AUTOSAR XML (schema 4.0)
standard types defined: float32, float64, sint16, sint32, sint8, uint16, uint32, uint8, void, boolean
package /ImplDataTypes
  4 x impl type, all with category=TYPE_REFERENCE, implementation-data-type=uint8, type-emitter=RTE:
    MultiStateBtnType
    SeatModeBtnType
    SensorPositiontype
    SensorWeightType
package /MappingSets
  data type mapping set MappingSet: mode-request-type-map{implementation-data-type=uint8, mode-group=SeatCtrlMode}
package /PortInterfaces/ClientServer
  10 x client server interface:
    CsIf_HeightMotor
      operation Opr_HeightMotorMove
        arg Arg_step: type=uint8, direction=IN
    CsIf_HeightSensor
      operation HeightSensor_GetPosition
        arg position: type=SensorPositiontype, direction=OUT
    CsIf_InclineMotor
      operation Opr_InclineMotorMove
        arg Arg_step: type=uint8, direction=IN
    CsIf_InclineSensor
      operation InclineSensor_GetPosition
        arg position: type=uint32, direction=OUT
    CsIf_IoGetSensorPosition
      operation IoGet
        arg position: type=SensorPositiontype, direction=OUT
    CsIf_IoGetSensorWeight
      operation IoGet
        arg weight: type=uint8, direction=OUT
    CsIf_IoSetMotor
      operation IoSetForward
      operation IoSetReverse
    CsIf_SlideMotor
      operation Opr_SlideMotorMove
        arg Arg_step: type=uint8, direction=IN
    CsIf_SlideSensor
      operation SlideSensor_GetPosition
        arg position: type=SensorPositiontype, direction=OUT
    CsIf_WeightSensor
      operation GetWeight
        arg weight: type=SensorWeightType, direction=OUT
package /PortInterfaces/ModeSwitch
  mode switch interface MsIf_SeatCtrlMode
    mode group SeatCtrlMode: type=SeatCtrlMode
  mode declaration group SeatCtrlMode: category=ALPHABETIC_ORDER, initial-mode=INIT, on-transition-value=255
    mode AUTO
    mode INIT
    mode MANUAL
package /PortInterfaces/SenderReceiver
  sender receiver interface SrIf_SeatCtrlBtns
    data HeightBtnState: type=MultiStateBtnType
    data InclineBtnState: type=MultiStateBtnType
    data SlideBtnState: type=MultiStateBtnType
  sender receiver interface SrIf_SeatCtrlData
    data DE_Height: type=uint8
    data DE_Incline: type=uint8
    data DE_Slide: type=uint8
  sender receiver interface SrIf_SeatModeBtn
    data DE_SeatModeBtn: type=SeatModeBtnType
package /SoftwareComponents
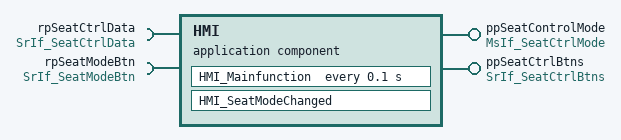
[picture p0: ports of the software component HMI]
  application sw component type HMI
    provide port ppSeatControlMode: provided-interface=MsIf_SeatCtrlMode
    provide port ppSeatCtrlBtns: provided-interface=SrIf_SeatCtrlBtns
    require port rpSeatCtrlData: required-interface=SrIf_SeatCtrlData
    require port rpSeatModeBtn: required-interface=SrIf_SeatModeBtn
    behavior Ibhv_HMI: data-type-mapping=MappingSet, handle-termination-and-restart=NO-SUPPORT
      data received event DRE_rpSeatModeBtn_DE_SeatModeBtn: start-on-event=HMI_SeatModeChanged, data=rpSeatModeBtn.DE_SeatModeBtn
      timing event TE_HMI_Mainfunction_100ms: start-on-event=HMI_Mainfunction, period=0.1
      runnable HMI_Mainfunction
        data-receive-point-by-arguments:
          access DRP_rpSeatCtrlData_DE_Height: accessed-variable=rpSeatCtrlData.DE_Height
          access DRP_rpSeatCtrlData_DE_Incline: accessed-variable=rpSeatCtrlData.DE_Incline
          access DRP_rpSeatCtrlData_DE_Slide: accessed-variable=rpSeatCtrlData.DE_Slide
        data-send-points:
          access DSP_ppSeatCtrlBtns_HeightBtnState: accessed-variable=ppSeatCtrlBtns.HeightBtnState
          access DSP_ppSeatCtrlBtns_InclineBtnState: accessed-variable=ppSeatCtrlBtns.InclineBtnState
          access DSP_ppSeatCtrlBtns_SlideBtnState: accessed-variable=ppSeatCtrlBtns.SlideBtnState
      runnable HMI_SeatModeChanged
        data-receive-point-by-arguments:
          access DRP_rpSeatModeBtn_DE_SeatModeBtn: accessed-variable=rpSeatModeBtn.DE_SeatModeBtn
        mode switch point MSP_ppSeatControlMode_ppSeatControlMode: mode-group=ppSeatControlMode.SeatCtrlMode
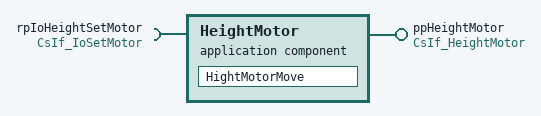
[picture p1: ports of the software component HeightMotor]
  application sw component type HeightMotor
    provide port ppHeightMotor: provided-interface=CsIf_HeightMotor
    require port rpIoHeightSetMotor: required-interface=CsIf_IoSetMotor
    behavior Ibhv_HeightMotor: data-type-mapping=MappingSet, handle-termination-and-restart=NO-SUPPORT
      operation invoked event OIE_ppHeightMotor_Opr_HeightMotorMove: start-on-event=HightMotorMove, operation=ppHeightMotor.Opr_HeightMotorMove
      runnable HightMotorMove
        sync call SCP_rpIoHeightSetMotor_IoSetForward: operation=rpIoHeightSetMotor.IoSetForward, timeout=0.0
        sync call SCP_rpIoHeightSetMotor_IoSetReverse: operation=rpIoHeightSetMotor.IoSetReverse, timeout=0.0
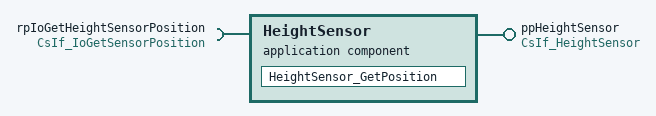
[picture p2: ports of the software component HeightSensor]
  application sw component type HeightSensor
    provide port ppHeightSensor: provided-interface=CsIf_HeightSensor
    require port rpIoGetHeightSensorPosition: required-interface=CsIf_IoGetSensorPosition
    behavior Ibhv_HeightSensor: data-type-mapping=MappingSet, handle-termination-and-restart=NO-SUPPORT
      operation invoked event OIE_ppHeightSensor_HeightSensor_GetPosition: start-on-event=HeightSensor_GetPosition, operation=ppHeightSensor.HeightSensor_GetPosition
      runnable HeightSensor_GetPosition
        sync call SCP_rpIoGetHeightSensorPosition_IoGet: operation=rpIoGetHeightSensorPosition.IoGet, timeout=0.0
  10 x swc implementation, all with programming-language=C, sw-version=1.0.0, vendor-id=255:
    Impl_HMI: behavior=Ibhv_HMI
      code-descriptors:
        code Code: artifact-descriptors=autosar-engineering-object={short-label=SWC.c, category=SWSRC}
      resource consumption ResourceConsumption
    Impl_HeightMotor: behavior=Ibhv_HeightMotor
      code-descriptors:
        code Code: artifact-descriptors=autosar-engineering-object={short-label=SWC.c, category=SWSRC}
      resource consumption ResourceConsumption
    Impl_HeightSensor: behavior=Ibhv_HeightSensor
      code-descriptors:
        code Code: artifact-descriptors=autosar-engineering-object={short-label=SWC.c, category=SWSRC}
      resource consumption ResourceConsumption
    Impl_InclineMotor: behavior=Ibhv_InclineMotor
      code-descriptors:
        code Code: artifact-descriptors=autosar-engineering-object={short-label=SWC.c, category=SWSRC}
      resource consumption ResourceConsumption
    Impl_InclineSensor: behavior=Ibhv_InclineSensor
      code-descriptors:
        code Code: artifact-descriptors=autosar-engineering-object={short-label=SWC.c, category=SWSRC}
      resource consumption ResourceConsumption
    Impl_IoHwAbs: behavior=Ibhv_IoHwAbs
      code-descriptors:
        code Code: artifact-descriptors=autosar-engineering-object={short-label=SWC.c, category=SWSRC}
      resource consumption ResourceConsumption
    Impl_Seat_Manager: behavior=Ibhv_Seat_Manager
      code-descriptors:
        code Code: artifact-descriptors=autosar-engineering-object={short-label=SWC.c, category=SWSRC}
      resource consumption ResourceConsumption
    Impl_SlideMotor: behavior=Ibhv_SlideMotor
      code-descriptors:
        code Code: artifact-descriptors=autosar-engineering-object={short-label=SWC.c, category=SWSRC}
      resource consumption ResourceConsumption
    Impl_SlideSensor: behavior=Ibhv_SlideSensor
      code-descriptors:
        code Code: artifact-descriptors=autosar-engineering-object={short-label=SWC.c, category=SWSRC}
      resource consumption ResourceConsumption
    Impl_WeightSensor: behavior=Ibhv_WeightSensor
      code-descriptors:
        code Code: artifact-descriptors=autosar-engineering-object={short-label=SWC.c, category=SWSRC}
      resource consumption ResourceConsumption
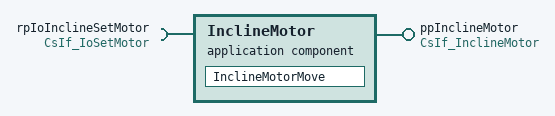
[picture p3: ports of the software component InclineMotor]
  application sw component type InclineMotor
    provide port ppInclineMotor: provided-interface=CsIf_InclineMotor
    require port rpIoInclineSetMotor: required-interface=CsIf_IoSetMotor
    behavior Ibhv_InclineMotor: data-type-mapping=MappingSet, handle-termination-and-restart=NO-SUPPORT
      operation invoked event OIE_ppInclineMotor_Opr_InclineMotorMove: start-on-event=InclineMotorMove, operation=ppInclineMotor.Opr_InclineMotorMove
      runnable InclineMotorMove
        sync call SCP_rpIoInclineSetMotor_IoSetForward: operation=rpIoInclineSetMotor.IoSetForward, timeout=0.0
        sync call SCP_rpIoInclineSetMotor_IoSetReverse: operation=rpIoInclineSetMotor.IoSetReverse, timeout=0.0
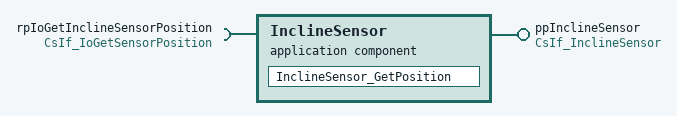
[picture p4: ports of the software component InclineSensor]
  application sw component type InclineSensor
    provide port ppInclineSensor: provided-interface=CsIf_InclineSensor
    require port rpIoGetInclineSensorPosition: required-interface=CsIf_IoGetSensorPosition
    behavior Ibhv_InclineSensor: data-type-mapping=MappingSet, handle-termination-and-restart=NO-SUPPORT
      operation invoked event OIE_ppInclineSensor_InclineSensor_GetPosition: start-on-event=InclineSensor_GetPosition, operation=ppInclineSensor.InclineSensor_GetPosition
      runnable InclineSensor_GetPosition
        sync call SCP_rpIoGetInclineSensorPosition_IoGet: operation=rpIoGetInclineSensorPosition.IoGet, timeout=0.0
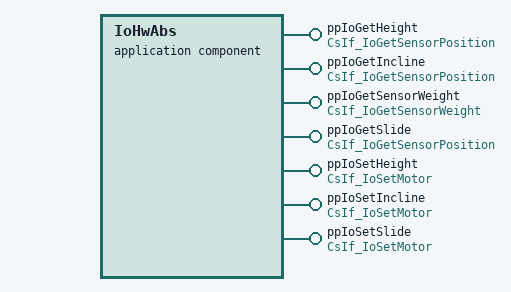
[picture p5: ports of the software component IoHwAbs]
  application sw component type IoHwAbs
    7 x provide port:
      ppIoGetHeight: provided-interface=CsIf_IoGetSensorPosition
      ppIoGetIncline: provided-interface=CsIf_IoGetSensorPosition
      ppIoGetSensorWeight: provided-interface=CsIf_IoGetSensorWeight
      ppIoGetSlide: provided-interface=CsIf_IoGetSensorPosition
      ppIoSetHeight: provided-interface=CsIf_IoSetMotor
      ppIoSetIncline: provided-interface=CsIf_IoSetMotor
      ppIoSetSlide: provided-interface=CsIf_IoSetMotor
    behavior Ibhv_IoHwAbs: data-type-mapping=MappingSet, handle-termination-and-restart=NO-SUPPORT
      10 x operation invoked event:
        OIE_ppIoGetHeight_IoGet: start-on-event=IoHwAbs_EcuGet_Height, operation=ppIoGetHeight.IoGet
        OIE_ppIoGetIncline_IoGet: start-on-event=IoHwAbs_EcuGet_Incline, operation=ppIoGetIncline.IoGet
        OIE_ppIoGetSensorWeight_IoGet: start-on-event=IoHwAbs_EcuGet_Weight, operation=ppIoGetSensorWeight.IoGet
        OIE_ppIoGetSlide_IoGet: start-on-event=IoHwAbs_EcuGet_Slide, operation=ppIoGetSlide.IoGet
        OIE_ppIoSetHeight_IoSetForward: start-on-event=IoHwAbs_EcuSetForward_Height, operation=ppIoSetHeight.IoSetForward
        OIE_ppIoSetHeight_IoSetReverse: start-on-event=IoHwAbs_EcuSetReverse_Height, operation=ppIoSetHeight.IoSetReverse
        OIE_ppIoSetIncline_IoSetForward: start-on-event=IoHwAbs_EcuSetForward_Incline, operation=ppIoSetIncline.IoSetForward
        OIE_ppIoSetIncline_IoSetReverse: start-on-event=IoHwAbs_EcuSetReverse_Incline, operation=ppIoSetIncline.IoSetReverse
        OIE_ppIoSetSlide_IoSetForward: start-on-event=IoHwAbs_EcuSetForward_Slide, operation=ppIoSetSlide.IoSetForward
        OIE_ppIoSetSlide_IoSetReverse: start-on-event=IoHwAbs_EcuSetReverse_Slide, operation=ppIoSetSlide.IoSetReverse
      10 x runnable:
        IoHwAbs_EcuGet_Height
        IoHwAbs_EcuGet_Incline
        IoHwAbs_EcuGet_Slide
        IoHwAbs_EcuGet_Weight
        IoHwAbs_EcuSetForward_Height
        IoHwAbs_EcuSetForward_Incline
        IoHwAbs_EcuSetForward_Slide
        IoHwAbs_EcuSetReverse_Height
        IoHwAbs_EcuSetReverse_Incline
        IoHwAbs_EcuSetReverse_Slide
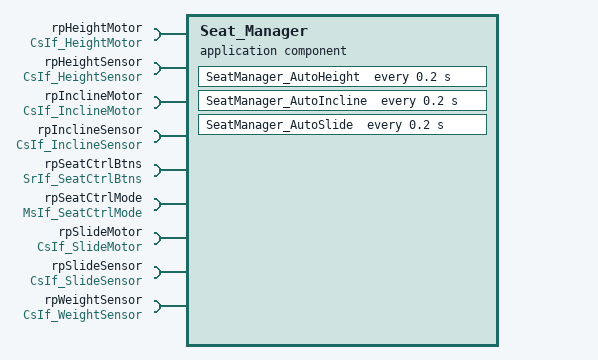
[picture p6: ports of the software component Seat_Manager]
  application sw component type Seat_Manager
    9 x require port:
      rpHeightMotor: required-interface=CsIf_HeightMotor
      rpHeightSensor: required-interface=CsIf_HeightSensor
      rpInclineMotor: required-interface=CsIf_InclineMotor
      rpInclineSensor: required-interface=CsIf_InclineSensor
      rpSeatCtrlBtns: required-interface=SrIf_SeatCtrlBtns
      rpSeatCtrlMode: required-interface=MsIf_SeatCtrlMode
      rpSlideMotor: required-interface=CsIf_SlideMotor
      rpSlideSensor: required-interface=CsIf_SlideSensor
      rpWeightSensor: required-interface=CsIf_WeightSensor
    behavior Ibhv_Seat_Manager: data-type-mapping=MappingSet, handle-termination-and-restart=NO-SUPPORT
      data received event DRE_rpSeatCtrlBtns_HeightBtnState: start-on-event=SeatManager_SetHeight, data=rpSeatCtrlBtns.HeightBtnState
      data received event DRE_rpSeatCtrlBtns_InclineBtnState: start-on-event=SeatManager_SetIncline, data=rpSeatCtrlBtns.InclineBtnState
      data received event DRE_rpSeatCtrlBtns_SlideBtnState: start-on-event=SeatManager_SetSlide, data=rpSeatCtrlBtns.SlideBtnState
      timing event TE_SeatManager_AutoHeight_200ms: start-on-event=SeatManager_AutoHeight, period=0.2
      timing event TE_SeatManager_AutoIncline_200ms: start-on-event=SeatManager_AutoIncline, period=0.2
      timing event TE_SeatManager_AutoSlide_200ms: start-on-event=SeatManager_AutoSlide, period=0.2
      6 x runnable:
        SeatManager_AutoHeight
          sync call SCP_rpHeightMotor_Opr_HeightMotorMove: operation=rpHeightMotor.Opr_HeightMotorMove, timeout=0.0
          sync call SCP_rpHeightSensor_HeightSensor_GetPosition: operation=rpHeightSensor.HeightSensor_GetPosition, timeout=0.0
          sync call SCP_rpWeightSensor_GetWeight: operation=rpWeightSensor.GetWeight, timeout=0.0
        SeatManager_AutoIncline
          sync call SCP_rpInclineMotor_Opr_InclineMotorMove: operation=rpInclineMotor.Opr_InclineMotorMove, timeout=0.0
          sync call SCP_rpInclineSensor_InclineSensor_GetPosition: operation=rpInclineSensor.InclineSensor_GetPosition, timeout=0.0
          sync call SCP_rpWeightSensor_GetWeight: operation=rpWeightSensor.GetWeight, timeout=0.0
        SeatManager_AutoSlide
          sync call SCP_rpSlideMotor_Opr_SlideMotorMove: operation=rpSlideMotor.Opr_SlideMotorMove, timeout=0.0
          sync call SCP_rpSlideSensor_SlideSensor_GetPosition: operation=rpSlideSensor.SlideSensor_GetPosition, timeout=0.0
          sync call SCP_rpWeightSensor_GetWeight: operation=rpWeightSensor.GetWeight, timeout=0.0
        SeatManager_SetHeight
          data-receive-point-by-arguments:
            access DRP_rpSeatCtrlBtns_HeightBtnState: accessed-variable=rpSeatCtrlBtns.HeightBtnState
          sync call SCP_rpHeightMotor_Opr_HeightMotorMove: operation=rpHeightMotor.Opr_HeightMotorMove, timeout=0.0
        SeatManager_SetIncline
          data-receive-point-by-arguments:
            access DRP_rpSeatCtrlBtns_InclineBtnState: accessed-variable=rpSeatCtrlBtns.InclineBtnState
          sync call SCP_rpInclineMotor_Opr_InclineMotorMove: operation=rpInclineMotor.Opr_InclineMotorMove, timeout=0.0
        SeatManager_SetSlide
          data-receive-point-by-arguments:
            access DRP_rpSeatCtrlBtns_SlideBtnState: accessed-variable=rpSeatCtrlBtns.SlideBtnState
          sync call SCP_rpSlideMotor_Opr_SlideMotorMove: operation=rpSlideMotor.Opr_SlideMotorMove, timeout=0.0
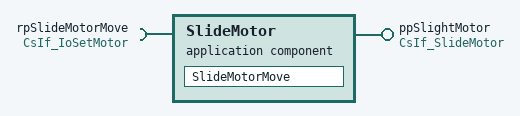
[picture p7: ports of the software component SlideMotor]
  application sw component type SlideMotor
    provide port ppSlightMotor: provided-interface=CsIf_SlideMotor
    require port rpSlideMotorMove: required-interface=CsIf_IoSetMotor
    behavior Ibhv_SlideMotor: data-type-mapping=MappingSet, handle-termination-and-restart=NO-SUPPORT
      operation invoked event OIE_ppSlightMotor_Opr_SlideMotorMove: start-on-event=SlideMotorMove, operation=ppSlightMotor.Opr_SlideMotorMove
      runnable SlideMotorMove
        sync call SCP_rpSlideMotorMove_IoSetForward: operation=rpSlideMotorMove.IoSetForward, timeout=0.0
        sync call SCP_rpSlideMotorMove_IoSetReverse: operation=rpSlideMotorMove.IoSetReverse, timeout=0.0
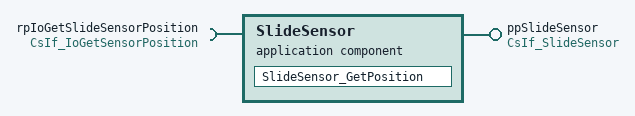
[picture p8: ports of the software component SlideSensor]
  application sw component type SlideSensor
    provide port ppSlideSensor: provided-interface=CsIf_SlideSensor
    require port rpIoGetSlideSensorPosition: required-interface=CsIf_IoGetSensorPosition
    behavior Ibhv_SlideSensor: data-type-mapping=MappingSet, handle-termination-and-restart=NO-SUPPORT
      operation invoked event OIE_ppSlideSensor_SlideSensor_GetPosition: start-on-event=SlideSensor_GetPosition, operation=ppSlideSensor.SlideSensor_GetPosition
      runnable SlideSensor_GetPosition
        sync call SCP_rpIoGetSlideSensorPosition_IoGet: operation=rpIoGetSlideSensorPosition.IoGet, timeout=0.0
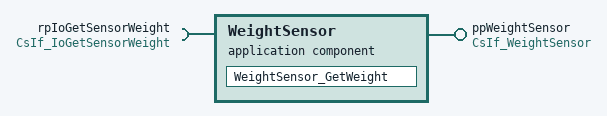
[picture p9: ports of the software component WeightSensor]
  application sw component type WeightSensor
    provide port ppWeightSensor: provided-interface=CsIf_WeightSensor
    require port rpIoGetSensorWeight: required-interface=CsIf_IoGetSensorWeight
    behavior Ibhv_WeightSensor: data-type-mapping=MappingSet, handle-termination-and-restart=NO-SUPPORT
      operation invoked event OIE_ppWeightSensor_GetWeight: start-on-event=WeightSensor_GetWeight, operation=ppWeightSensor.GetWeight
      runnable WeightSensor_GetWeight
        sync call SCP_rpIoGetSensorWeight_IoGet: operation=rpIoGetSensorWeight.IoGet, timeout=0.0
package /Compositions
  composition sw component type TestAppComposition
